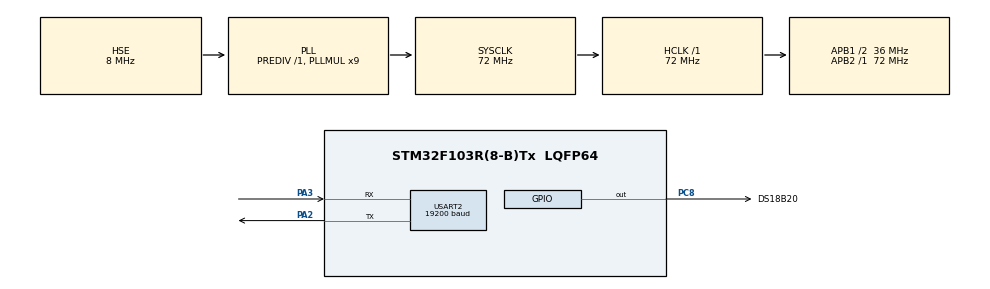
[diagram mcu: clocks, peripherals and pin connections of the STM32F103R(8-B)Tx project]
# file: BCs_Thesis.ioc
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Mcu.Family=STM32F1
Mcu.Name=STM32F103R(8-B)Tx
Mcu.Package=LQFP64
NVIC.PriorityGroup=NVIC_PRIORITYGROUP_4
NVIC.RCC_IRQn=true\:0\:0\:false\:false\:true\:true\:false
PA2.Mode=Asynchronous
PA2.Signal=USART2_TX
PA3.Mode=Asynchronous
PA3.Signal=USART2_RX
PC8.GPIO_Label=DS18B20
PC8.Signal=GPIO_Output
PD0-OSC_IN.Mode=HSE-External-Oscillator
PD0-OSC_IN.Signal=RCC_OSC_IN
PD1-OSC_OUT.Mode=HSE-External-Oscillator
PD1-OSC_OUT.Signal=RCC_OSC_OUT
ProjectManager.HeapSize=0x200
ProjectManager.StackSize=0x400
ProjectManager.TargetToolchain=STM32CubeIDE
RCC.AHBFreq_Value=72000000
RCC.APB1CLKDivider=RCC_HCLK_DIV2
RCC.APB1Freq_Value=36000000
RCC.APB1TimFreq_Value=72000000
RCC.APB2Freq_Value=72000000
RCC.APB2TimFreq_Value=72000000
RCC.HCLKFreq_Value=72000000
RCC.PLLMUL=RCC_PLL_MUL9
RCC.PLLSourceVirtual=RCC_PLLSOURCE_HSE
RCC.SYSCLKFreq_VALUE=72000000
RCC.SYSCLKSource=RCC_SYSCLKSOURCE_PLLCLK
RCC.USBFreq_Value=72000000
TIM1.Period=0xffff-1
TIM1.Prescaler=72-1
USART2.BaudRate=19200
USART2.VirtualMode=VM_ASYNC
VP_CRC_VS_CRC.Mode=CRC_Activate
VP_SYS_VS_ND.Mode=No_Debug
VP_TIM1_VS_ClockSourceINT.Mode=Internal
board=custom

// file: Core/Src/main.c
/* USER CODE BEGIN Header */
/**
  ******************************************************************************
  * @file           : main.c
  * @brief          : Main program body
  ******************************************************************************
  * @attention
  *
  * <h2><center>&copy; Copyright (c) 2020 STMicroelectronics.
  * All rights reserved.</center></h2>
  *
  * This software component is licensed by ST under BSD 3-Clause license,
  * the "License"; You may not use this file except in compliance with the
  * License. You may obtain a copy of the License at:
  *                        opensource.org/licenses/BSD-3-Clause
  *
  ******************************************************************************
  */
/* USER CODE END Header */

#include "main.h"
#include "crc.h"
#include "tim.h"
#include "usart.h"
#include "gpio.h"

/* USER CODE BEGIN Includes */
#include "onewire.h"
#include "ds18b20.h"
#include "string.h"
#include <stdio.h>
/* USER CODE END Includes */

/* USER CODE BEGIN PV */
float temperature;
char message[16];
/* USER CODE END PV */

void SystemClock_Config(void);

/* USER CODE BEGIN 0 */
void OneWire_Delay(uint16_t us)
{
	  __HAL_TIM_SET_COUNTER(&htim1,0);
	    while ((__HAL_TIM_GET_COUNTER(&htim1))<us);
}

/* USER CODE END 0 */

int main(void)
{

  /* MCU Configuration--------------------------------------------------------*/

  /* Reset of all peripherals, Initializes the Flash interface and the Systick. */
  HAL_Init();

  /* Configure the system clock */
  SystemClock_Config();

  /* Initialize all configured peripherals */
  MX_GPIO_Init();
  MX_USART2_UART_Init();
  MX_CRC_Init();
  MX_TIM1_Init();
  /* USER CODE BEGIN 2 */
  HAL_TIM_Base_Start(&htim1);
  DS18B20_Init(DS18B20_Resolution_12bits);
  /* USER CODE END 2 */

  /* Infinite loop */
  /* USER CODE BEGIN WHILE */

  while (1)
  {

	  DS18B20_ReadAll();
	   DS18B20_StartAll();
	   uint8_t ROM_tmp[8];
	   uint8_t i;
	   for(i = 0; i < DS18B20_Quantity(); i++)
	   {
	     if(DS18B20_GetTemperature(i, &temperature))
	     {
	       DS18B20_GetROM(i, ROM_tmp);
	       memset(message, 0, sizeof(message));
	       sprintf(message, "Temp : %f", temperature);
	       HAL_UART_Transmit(&huart2, (uint8_t*)message, sizeof(message), 100);
	     }
	   }
	   HAL_Delay(1000);
    /* USER CODE END WHILE */

  }
}

void SystemClock_Config(void)
{
  RCC_OscInitTypeDef RCC_OscInitStruct = {0};
  RCC_ClkInitTypeDef RCC_ClkInitStruct = {0};

  /** Initializes the CPU, AHB and APB busses clocks
  */
  RCC_OscInitStruct.OscillatorType = RCC_OSCILLATORTYPE_HSE;
  RCC_OscInitStruct.HSEState = RCC_HSE_ON;
  RCC_OscInitStruct.HSEPredivValue = RCC_HSE_PREDIV_DIV1;
  RCC_OscInitStruct.HSIState = RCC_HSI_ON;
  RCC_OscInitStruct.PLL.PLLState = RCC_PLL_ON;
  RCC_OscInitStruct.PLL.PLLSource = RCC_PLLSOURCE_HSE;
  RCC_OscInitStruct.PLL.PLLMUL = RCC_PLL_MUL9;
  if (HAL_RCC_OscConfig(&RCC_OscInitStruct) != HAL_OK)
  {
    Error_Handler();
  }
  /** Initializes the CPU, AHB and APB busses clocks
  */
  RCC_ClkInitStruct.ClockType = RCC_CLOCKTYPE_HCLK|RCC_CLOCKTYPE_SYSCLK
                              |RCC_CLOCKTYPE_PCLK1|RCC_CLOCKTYPE_PCLK2;
  RCC_ClkInitStruct.SYSCLKSource = RCC_SYSCLKSOURCE_PLLCLK;
  RCC_ClkInitStruct.AHBCLKDivider = RCC_SYSCLK_DIV1;
  RCC_ClkInitStruct.APB1CLKDivider = RCC_HCLK_DIV2;
  RCC_ClkInitStruct.APB2CLKDivider = RCC_HCLK_DIV1;

  if (HAL_RCC_ClockConfig(&RCC_ClkInitStruct, FLASH_LATENCY_2) != HAL_OK)
  {
    Error_Handler();
  }
}

void Error_Handler(void)
{
}

/************************ (C) COPYRIGHT STMicroelectronics *****END OF FILE****/
